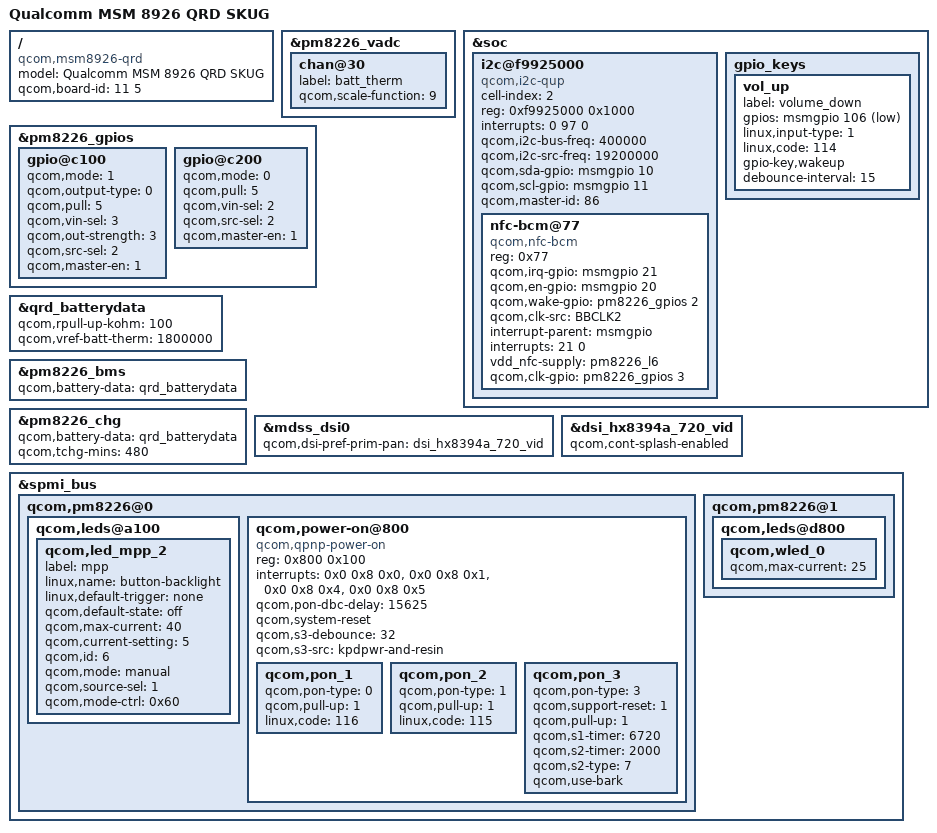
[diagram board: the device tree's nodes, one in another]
/* Copyright (c) 2013-2014, The Linux Foundation. All rights reserved.
 *
 * This program is free software; you can redistribute it and/or modify
 * it under the terms of the GNU General Public License version 2 and
 * only version 2 as published by the Free Software Foundation.
 *
 * This program is distributed in the hope that it will be useful,
 * but WITHOUT ANY WARRANTY; without even the implied warranty of
 * MERCHANTABILITY or FITNESS FOR A PARTICULAR PURPOSE.  See the
 * GNU General Public License for more details.
 */

/dts-v1/;
/include/ "msm8926-v2.dtsi"
/include/ "msm8926-qrd-skug.dtsi"

/ {
	model = "Qualcomm MSM 8926 QRD SKUG";
	compatible = "qcom,msm8926-qrd", "qcom,msm8926", "qcom,qrd";
	qcom,board-id = <11 5>;
};
/*xiangdong add for k-touch therm config*/
&pm8226_vadc {
	chan@30 {
		label = "batt_therm";
		qcom,scale-function = <9>;
	};
};
/*xiangdong add for nfc begin*/
&soc {
	i2c@f9925000 { /* BLSP1 QUP3 */
		cell-index = <2>;
		compatible = "qcom,i2c-qup";
		reg = <0xf9925000 0x1000>;
		#address-cells = <1>;
		#size-cells = <0>;
		reg-names = "qup_phys_addr";
		interrupts = <0 97 0>;
		interrupt-names = "qup_err_intr";
		qcom,i2c-bus-freq = <400000>;
		qcom,i2c-src-freq = <19200000>;
		qcom,sda-gpio = <&msmgpio 10 0>;
		qcom,scl-gpio = <&msmgpio 11 0>;
		qcom,master-id = <86>;

		nfc-bcm@77 {
			compatible = "qcom,nfc-bcm";
			reg = <0x77>;
			qcom,irq-gpio = <&msmgpio 21 0x00>;
			qcom,en-gpio = <&msmgpio 20 0x00>;
			qcom,wake-gpio = <&pm8226_gpios 2 0>;
			qcom,clk-src = "BBCLK2";
			interrupt-parent = <&msmgpio>;
			interrupts = <21 0>;
			vdd_nfc-supply = <&pm8226_l6>;
			qcom,clk-gpio = <&pm8226_gpios 3 0>;
		};
	};
	gpio_keys {
		vol_up {
			label = "volume_down";
			gpios = <&msmgpio 106 0x1>;
			linux,input-type = <1>;
			linux,code = <114>;
			gpio-key,wakeup;
			debounce-interval = <15>;
		};
	};
};
&pm8226_gpios {
	gpio@c100 { /* GPIO 2 */
		qcom,mode = <1>;		/* Digital output */
		qcom,output-type = <0>;		/* CMOS logic */
		qcom,pull = <5>;		/* QPNP_PIN_PULL_NO*/
		qcom,vin-sel = <3>;		/* QPNP_PIN_VIN3 */
		qcom,out-strength = <3>;	/* QPNP_PIN_OUT_STRENGTH_HIGH */
		qcom,src-sel = <2>;		/* QPNP_PIN_SEL_FUNC_1 */
		qcom,master-en = <1>;		/* Enable GPIO */
	};

	gpio@c200 { /* GPIO 3 */
		qcom,mode = <0>;		/* QPNP_PIN_MODE_DIG_IN */
		qcom,pull = <5>;		/* QPNP_PIN_PULL_NO */
		qcom,vin-sel = <2>;		/* QPNP_PIN_VIN2 */
		qcom,src-sel = <2>;		/* QPNP_PIN_SEL_FUNC_1 */
		qcom,master-en = <1>;
	};
};
/*xiangdong add for nfc end*/
/*xiangdong add for battery begin*/
&qrd_batterydata {
	qcom,rpull-up-kohm = <100>;
	qcom,vref-batt-therm = <1800000>;

	/include/ "batterydata-qrd-4v2-2000mah.dtsi"
	/include/ "TY_batterydata-qrd-4v35-2200mah.dtsi"
	/include/ "TY_batterydata-qrd-LS-4v33-2250mah.dtsi"
};

&pm8226_bms {
	qcom,battery-data = <&qrd_batterydata>;
};

&pm8226_chg {
	qcom,battery-data = <&qrd_batterydata>;
	qcom,tchg-mins = <480>;
};
/*xiangdong add for battery end*/

&mdss_dsi0 {
	qcom,dsi-pref-prim-pan = <&dsi_hx8394a_720_vid>;
};
&dsi_hx8394a_720_vid{
	qcom,cont-splash-enabled;
};

&spmi_bus {
	qcom,pm8226@0 {
		qcom,leds@a100 {
			status = "okay";
			qcom,led_mpp_2 {
				label = "mpp";
				linux,name = "button-backlight";
				linux,default-trigger = "none";
				qcom,default-state = "off";
				qcom,max-current = <40>;
				qcom,current-setting = <5>;
				qcom,id = <6>;
				qcom,mode = "manual";
				qcom,source-sel = <1>;
				qcom,mode-ctrl = <0x60>;
				};
			};
		qcom,power-on@800 {
			compatible = "qcom,qpnp-power-on";
			reg = <0x800 0x100>;
			interrupts = <0x0 0x8 0x0>,
				     <0x0 0x8 0x1>,
				     <0x0 0x8 0x4>,
				     <0x0 0x8 0x5>;
			interrupt-names = "kpdpwr", "resin",
					"resin-bark", "kpdpwr-resin-bark";
			qcom,pon-dbc-delay = <15625>;
			qcom,system-reset;
			qcom,s3-debounce = <32>;
			qcom,s3-src = "kpdpwr-and-resin";

			qcom,pon_1 {
				qcom,pon-type = <0>;
				qcom,pull-up = <1>;
				linux,code = <116>;
			};

			qcom,pon_2 {
				qcom,pon-type = <1>;
				qcom,pull-up = <1>;
				linux,code = <115>;
			};

			qcom,pon_3 {
				qcom,pon-type = <3>;
				qcom,support-reset = <1>;
				qcom,pull-up = <1>;
				qcom,s1-timer = <6720>;
				qcom,s2-timer = <2000>;
				qcom,s2-type = <7>;
				qcom,use-bark;
			};
		};
	};
	qcom,pm8226@1 {
		qcom,leds@d800 {
			qcom,wled_0 {
				qcom,max-current = <25>;
			};
		};
	};
};
